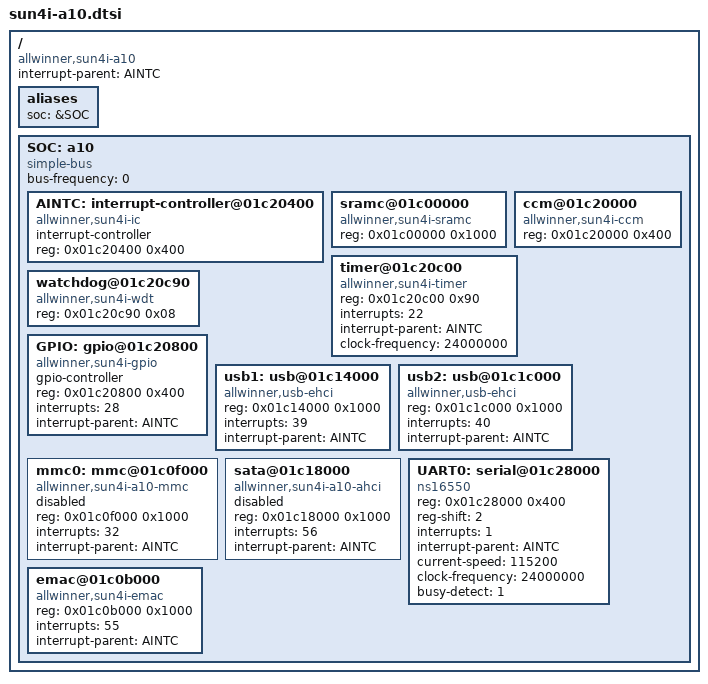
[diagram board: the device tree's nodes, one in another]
/*-
 * Copyright (c) 2014 Ganbold Tsagaankhuu <ganbold@freebsd.org>
 * All rights reserved.
 *
 * Redistribution and use in source and binary forms, with or without
 * modification, are permitted provided that the following conditions
 * are met:
 * 1. Redistributions of source code must retain the above copyright
 *    notice, this list of conditions and the following disclaimer.
 * 2. Redistributions in binary form must reproduce the above copyright
 *    notice, this list of conditions and the following disclaimer in the
 *    documentation and/or other materials provided with the distribution.
 *
 * THIS SOFTWARE IS PROVIDED BY THE AUTHOR AND CONTRIBUTORS ``AS IS'' AND
 * ANY EXPRESS OR IMPLIED WARRANTIES, INCLUDING, BUT NOT LIMITED TO, THE
 * IMPLIED WARRANTIES OF MERCHANTABILITY AND FITNESS FOR A PARTICULAR PURPOSE
 * ARE DISCLAIMED.  IN NO EVENT SHALL THE AUTHOR OR CONTRIBUTORS BE LIABLE
 * FOR ANY DIRECT, INDIRECT, INCIDENTAL, SPECIAL, EXEMPLARY, OR CONSEQUENTIAL
 * DAMAGES (INCLUDING, BUT NOT LIMITED TO, PROCUREMENT OF SUBSTITUTE GOODS
 * OR SERVICES; LOSS OF USE, DATA, OR PROFITS; OR BUSINESS INTERRUPTION)
 * HOWEVER CAUSED AND ON ANY THEORY OF LIABILITY, WHETHER IN CONTRACT, STRICT
 * LIABILITY, OR TORT (INCLUDING NEGLIGENCE OR OTHERWISE) ARISING IN ANY WAY
 * OUT OF THE USE OF THIS SOFTWARE, EVEN IF ADVISED OF THE POSSIBILITY OF
 * SUCH DAMAGE.
 *
 * $FreeBSD$
 */

/ {
	compatible = "allwinner,sun4i-a10";
	#address-cells = <1>;
	#size-cells = <1>;

	interrupt-parent = <&AINTC>;

	aliases {
		soc = &SOC;
	};

	SOC: a10 {
		#address-cells = <1>;
		#size-cells = <1>;
		compatible = "simple-bus";
		ranges;
		bus-frequency = <0>;

		AINTC: interrupt-controller@01c20400 {
			compatible = "allwinner,sun4i-ic";
			interrupt-controller;
			#address-cells = <0>;
			#interrupt-cells = <1>;
			reg =   < 0x01c20400 0x400 >;
		};

		sramc@01c00000 {
			compatible = "allwinner,sun4i-sramc";
			#address-cells = <1>;
			#size-cells = <1>;
			reg = < 0x01c00000 0x1000 >;
		};

		ccm@01c20000 {
			compatible = "allwinner,sun4i-ccm";
			#address-cells = <1>;
			#size-cells = <1>;
			reg = < 0x01c20000 0x400 >;
		};

		timer@01c20c00 {
			compatible = "allwinner,sun4i-timer";
			reg = <0x01c20c00 0x90>;
			interrupts = < 22 >;
			interrupt-parent = <&AINTC>;
			clock-frequency = < 24000000 >;
		};

		watchdog@01c20c90 {
			compatible = "allwinner,sun4i-wdt";
			reg = <0x01c20c90 0x08>;
		};


		GPIO: gpio@01c20800 {
			#gpio-cells = <3>;
			compatible = "allwinner,sun4i-gpio";
			gpio-controller;
			reg =<  0x01c20800 0x400 >;
			interrupts = < 28 >;
			interrupt-parent = <&AINTC>;
		};

		usb1: usb@01c14000 {
			compatible = "allwinner,usb-ehci", "usb-ehci";
			reg = <0x01c14000 0x1000>;
			interrupts = < 39 >;
			interrupt-parent = <&AINTC>;
		};

		usb2: usb@01c1c000 {
			compatible = "allwinner,usb-ehci", "usb-ehci";
			reg = <0x01c1c000 0x1000>;
			interrupts = < 40 >;
			interrupt-parent = <&AINTC>;
		};

		mmc0: mmc@01c0f000 {
			compatible = "allwinner,sun4i-a10-mmc";
			reg = <0x01c0f000 0x1000>;
			interrupts = <32>;
			interrupt-parent = <&AINTC>;
			status = "disabled";
		};

		sata@01c18000 {
			compatible = "allwinner,sun4i-a10-ahci";
			reg = <0x01c18000 0x1000>;
			interrupts = <56>;
			interrupt-parent = <&AINTC>;
			status = "disabled";
		};

		UART0: serial@01c28000 {
			compatible = "ns16550";
			reg = <0x01c28000 0x400>;
			reg-shift = <2>;
			interrupts = <1>;
			interrupt-parent = <&AINTC>;
			current-speed = <115200>;
			clock-frequency = < 24000000 >;
			busy-detect = <1>;
		};

		emac@01c0b000 {
			compatible = "allwinner,sun4i-emac";
			reg = <0x01c0b000 0x1000>;
			interrupts = <55>;
			interrupt-parent = <&AINTC>;
		};
	};
};

